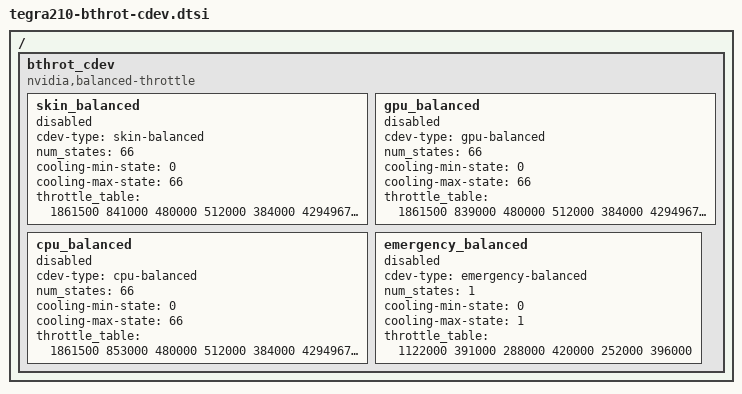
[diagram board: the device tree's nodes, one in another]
/*
 * arch/arm64/boot/dts/tegra210-platforms/tegra210-bthrot-cdev.dtsi
 *
 * Copyright (c) 2014, NVIDIA CORPORATION.  All rights reserved.
 *
 * This program is free software; you can redistribute it and/or modify
 * it under the terms of the GNU General Public License as published by
 * the Free Software Foundation; version 2 of the License.
 *
 * This program is distributed in the hope that it will be useful, but WITHOUT
 * ANY WARRANTY; without even the implied warranty of MERCHANTABILITY or
 * FITNESS FOR A PARTICULAR PURPOSE.  See the GNU General Public License for
 * more details.
 *
 * You should have received a copy of the GNU General Public License along
 * with this program; if not, write to the Free Software Foundation, Inc.,
 * 51 Franklin Street, Fifth Floor, Boston, MA  02110-1301, USA.
 *
 */

/{
	bthrot_cdev {
		compatible = "nvidia,balanced-throttle";
		skin_balanced {
			cdev-type = "skin-balanced";
			num_states = <66>;
			cooling-min-state = <0>;
			cooling-max-state = <66>;
			#cooling-cells = <2>;
			status = "disabled";
			throttle_table = <
			/*	CPU		GPU		C2BUS	C3BUS	SCLK	EMC	*/
				1861500	841000	480000	512000	384000	4294967295
				1836000	830000	480000	512000	384000	4294967295
				1810500	818000	480000	512000	384000	4294967295
				1785000	806000	480000	512000	384000	4294967295
				1759500	795000	480000	512000	384000	4294967295
				1734000	783000	480000	512000	384000	4294967295
				1708500	771000	480000	512000	384000	4294967295
				1683000	760000	480000	512000	384000	4294967295
				1657500	748000	480000	512000	384000	4294967295
				1632000	736000	480000	512000	384000	4294967295
				1606500	725000	480000	512000	384000	4294967295
				1581000	713000	480000	512000	384000	4294967295
				1555500	702000	480000	512000	384000	4294967295
				1530000	690000	480000	512000	384000	4294967295
				1504500	678000	480000	512000	384000	4294967295
				1479000	667000	480000	512000	384000	4294967295
				1453500	655000	480000	512000	384000	4294967295
				1428000	643000	480000	512000	384000	4294967295
				1402500	632000	480000	512000	384000	4294967295
				1377000	620000	480000	512000	384000	4294967295
				1351500	608000	480000	512000	384000	4294967295
				1326000	597000	480000	512000	384000	4294967295
				1300500	585000	480000	512000	384000	4294967295
				1275000	573000	480000	512000	384000	4294967295
				1249500	562000	480000	512000	384000	4294967295
				1224000	550000	480000	512000	384000	4294967295
				1198500	538000	480000	512000	384000	4294967295
				1173000	527000	480000	512000	384000	4294967295
				1147500	515000	480000	512000	384000	4294967295
				1122000	503000	480000	512000	384000	4294967295
				1096500	492000	480000	512000	384000	4294967295
				1071000	480000	480000	512000	384000	4294967295
				1045500	469000	480000	512000	384000	4294967295
				1020000	457000	480000	512000	384000	4294967295
				994500	445000	480000	512000	384000	4294967295
				969000	434000	480000	486400	384000	4294967295
				943500	422000	480000	486400	384000	4294967295
				918000	410000	480000	486400	384000	4294967295
				892500	399000	480000	486400	384000	4294967295
				867000	387000	480000	486400	384000	4294967295
				841500	375000	480000	486400	384000	4294967295
				816000	364000	480000	486400	384000	4294967295
				790500	352000	480000	486400	384000	4294967295
				765000	340000	480000	486400	384000	4294967295
				739500	329000	480000	473600	384000	4294967295
				714000	317000	480000	473600	384000	4294967295
				688500	305000	480000	473600	384000	4294967295
				663000	294000	480000	473600	384000	4294967295
				637500	282000	480000	473600	384000	4294967295
				612000	270000	480000	473600	384000	4294967295
				586500	259000	480000	473600	384000	4294967295
				561000	247000	480000	435200	384000	4294967295
				535500	235000	480000	435200	384000	4294967295
				510000	224000	480000	435200	384000	4294967295
				484500	212000	480000	435200	384000	4294967295
				459000	201000	480000	435200	384000	4294967295
				433500	189000	480000	435200	384000	4294967295
				408000	177000	480000	396800	384000	4294967295
				382500	166000	480000	396800	384000	4294967295
				357000	154000	480000	396800	384000	4294967295
				331500	142000	480000	396800	384000	4294967295
				306000	131000	480000	396800	384000	4294967295
				280500	119000	480000	396800	384000	4294967295
				255000	107000	480000	396800	384000	4294967295
				229500	96000	480000	396800	384000	4294967295
				204000	84000	480000	396800	384000	4294967295
			>;
		};
		gpu_balanced {
			cdev-type = "gpu-balanced";
			num_states = <66>;
			cooling-min-state = <0>;
			cooling-max-state = <66>;
			#cooling-cells = <2>;
			status = "disabled";
			throttle_table = <
			/*	CPU		GPU		C2BUS	C3BUS	SCLK	EMC	*/
				1861500	839000	480000	512000	384000	4294967295
				1836000	825000	480000	512000	384000	4294967295
				1810500	810000	480000	512000	384000	4294967295
				1785000	796000	480000	512000	384000	4294967295
				1759500	782000	480000	512000	384000	4294967295
				1734000	768000	480000	512000	384000	4294967295
				1708500	753000	480000	512000	384000	4294967295
				1683000	739000	480000	512000	384000	4294967295
				1657500	725000	480000	512000	384000	4294967295
				1632000	711000	480000	512000	384000	4294967295
				1606500	696000	480000	512000	384000	4294967295
				1581000	682000	480000	512000	384000	4294967295
				1555500	668000	480000	512000	384000	4294967295
				1530000	654000	480000	512000	384000	4294967295
				1504500	639000	480000	512000	384000	4294967295
				1479000	625000	480000	512000	384000	4294967295
				1453500	611000	480000	512000	384000	4294967295
				1428000	597000	480000	512000	384000	4294967295
				1402500	582000	480000	512000	384000	4294967295
				1377000	568000	480000	512000	384000	4294967295
				1351500	554000	480000	512000	384000	4294967295
				1326000	540000	480000	512000	384000	4294967295
				1300500	525000	480000	512000	384000	4294967295
				1275000	511000	480000	512000	384000	4294967295
				1249500	497000	480000	512000	384000	4294967295
				1224000	483000	480000	512000	384000	4294967295
				1198500	469000	480000	512000	384000	4294967295
				1173000	454000	480000	512000	384000	4294967295
				1147500	440000	480000	512000	384000	4294967295
				1122000	426000	480000	512000	384000	4294967295
				1096500	412000	480000	512000	384000	4294967295
				1071000	397000	480000	512000	384000	4294967295
				1045500	383000	480000	512000	384000	4294967295
				1020000	369000	480000	512000	384000	4294967295
				994500	355000	480000	512000	384000	4294967295
				969000	340000	480000	486400	384000	4294967295
				943500	326000	480000	486400	384000	4294967295
				918000	312000	480000	486400	384000	4294967295
				892500	298000	480000	486400	384000	4294967295
				867000	283000	480000	486400	384000	4294967295
				841500	269000	480000	486400	384000	4294967295
				816000	255000	480000	486400	384000	4294967295
				790500	241000	480000	486400	384000	4294967295
				765000	226000	480000	486400	384000	4294967295
				739500	212000	480000	473600	384000	4294967295
				714000	198000	480000	473600	384000	4294967295
				688500	184000	480000	473600	384000	4294967295
				663000	169000	480000	473600	384000	4294967295
				637500	155000	480000	473600	384000	4294967295
				612000	141000	480000	473600	384000	4294967295
				586500	127000	480000	473600	384000	4294967295
				561000	112000	480000	435200	384000	4294967295
				535500	98000	480000	435200	384000	4294967295
				510000	84000	480000	435200	384000	4294967295
				484500	84000	480000	435200	384000	4294967295
				459000	84000	480000	435200	384000	4294967295
				433500	84000	480000	435200	384000	4294967295
				408000	84000	480000	396800	384000	4294967295
				382500	84000	480000	396800	384000	4294967295
				357000	84000	480000	396800	384000	4294967295
				331500	84000	480000	396800	384000	4294967295
				306000	84000	480000	396800	384000	4294967295
				280500	84000	480000	396800	384000	4294967295
				255000	84000	480000	396800	384000	4294967295
				229500	84000	480000	396800	384000	4294967295
				204000	84000	480000	396800	384000	4294967295
			>;
		};
		cpu_balanced {
			cdev-type = "cpu-balanced";
			num_states = <66>;
			cooling-min-state = <0>;
			cooling-max-state = <66>;
			#cooling-cells = <2>;
			status = "disabled";
			throttle_table = <
			/*	CPU		GPU		C2BUS	C3BUS	SCLK	EMC	*/
				1861500	853000	480000	512000	384000	4294967295
				1836000	853000	480000	512000	384000	4294967295
				1810500	853000	480000	512000	384000	4294967295
				1785000	853000	480000	512000	384000	4294967295
				1759500	853000	480000	512000	384000	4294967295
				1734000	853000	480000	512000	384000	4294967295
				1708500	853000	480000	512000	384000	4294967295
				1683000	853000	480000	512000	384000	4294967295
				1657500	853000	480000	512000	384000	4294967295
				1632000	853000	480000	512000	384000	4294967295
				1606500	839000	480000	512000	384000	4294967295
				1581000	826000	480000	512000	384000	4294967295
				1555500	812000	480000	512000	384000	4294967295
				1530000	798000	480000	512000	384000	4294967295
				1504500	784000	480000	512000	384000	4294967295
				1479000	771000	480000	512000	384000	4294967295
				1453500	757000	480000	512000	384000	4294967295
				1428000	743000	480000	512000	384000	4294967295
				1402500	729000	480000	512000	384000	4294967295
				1377000	716000	480000	512000	384000	4294967295
				1351500	702000	480000	512000	384000	4294967295
				1326000	688000	480000	512000	384000	4294967295
				1300500	674000	480000	512000	384000	4294967295
				1275000	661000	480000	512000	384000	4294967295
				1249500	647000	480000	512000	384000	4294967295
				1224000	633000	480000	512000	384000	4294967295
				1198500	620000	480000	512000	384000	4294967295
				1173000	606000	480000	512000	384000	4294967295
				1147500	592000	480000	512000	384000	4294967295
				1122000	578000	480000	512000	384000	4294967295
				1096500	565000	480000	512000	384000	4294967295
				1071000	551000	480000	512000	384000	4294967295
				1045500	537000	480000	512000	384000	4294967295
				1020000	523000	480000	512000	384000	4294967295
				994500	510000	480000	512000	384000	4294967295
				969000	496000	480000	486400	384000	4294967295
				943500	482000	480000	486400	384000	4294967295
				918000	469000	480000	486400	384000	4294967295
				892500	455000	480000	486400	384000	4294967295
				867000	441000	480000	486400	384000	4294967295
				841500	427000	480000	486400	384000	4294967295
				816000	414000	480000	486400	384000	4294967295
				790500	400000	480000	486400	384000	4294967295
				765000	386000	480000	486400	384000	4294967295
				739500	372000	480000	473600	384000	4294967295
				714000	359000	480000	473600	384000	4294967295
				688500	345000	480000	473600	384000	4294967295
				663000	331000	480000	473600	384000	4294967295
				637500	317000	480000	473600	384000	4294967295
				612000	304000	480000	473600	384000	4294967295
				586500	290000	480000	473600	384000	4294967295
				561000	276000	480000	435200	384000	4294967295
				535500	263000	480000	435200	384000	4294967295
				510000	249000	480000	435200	384000	4294967295
				484500	235000	480000	435200	384000	4294967295
				459000	221000	480000	435200	384000	4294967295
				433500	208000	480000	435200	384000	4294967295
				408000	194000	480000	396800	384000	4294967295
				382500	180000	480000	396800	384000	4294967295
				357000	166000	480000	396800	384000	4294967295
				331500	153000	480000	396800	384000	4294967295
				306000	139000	480000	396800	384000	4294967295
				280500	125000	480000	396800	384000	4294967295
				255000	111000	480000	396800	384000	4294967295
				229500	98000	480000	396800	384000	4294967295
				204000	84000	480000	396800	384000	4294967295
			>;
		};
		emergency_balanced {
			cdev-type = "emergency-balanced";
			num_states = <1>;
			cooling-min-state = <0>;
			cooling-max-state = <1>;
			#cooling-cells = <2>;
			status = "disabled";
			throttle_table = <
				/*CPU		GPU		C2BUS		C3BUS		SCLK		EMC	*/
				1122000		391000		288000		420000		252000		396000
			>;
		};
	};
};
